AUTOSAR XML (schema 3-2-1)
package /SeatHeater/SeatSensorLeft_swc
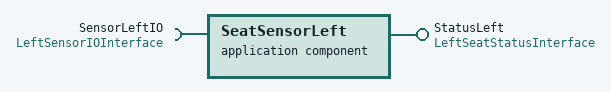
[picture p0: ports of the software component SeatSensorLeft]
  application software component type SeatSensorLeft
    provide port StatusLeft: unqueued-provider-com-spec{data-element=PassengerOnLeftSeat, alive-timeout=60.0}, provided-interface=LeftSeatStatusInterface
    require port SensorLeftIO: unqueued-provider-com-spec{data-element=LeftSensorValue, alive-timeout=60.0}, provided-interface=LeftSensorIOInterface
  internal behavior SeatSensorLeftBehavior: compontent=SeatSensorLeft
    timing event SeatSensorLeftUpdateTimer: start-on-event=SeatSensorRunnableLeft, period=0.0
    runnable SeatSensorRunnableLeft: can-be-invoked-concurrently=true
      data-read-access:
        dara read access SeatSensorLeftIOAccess: data-element=SensorLeftIO.LeftSensorValue
      data write access SeatSensorLeftStatusAccess: data-element=StatusLeft.PassengerOnLeftSeat
  swc implementation SeatSensorLeftImplementation: behavior=SeatSensorLeftBehavior
